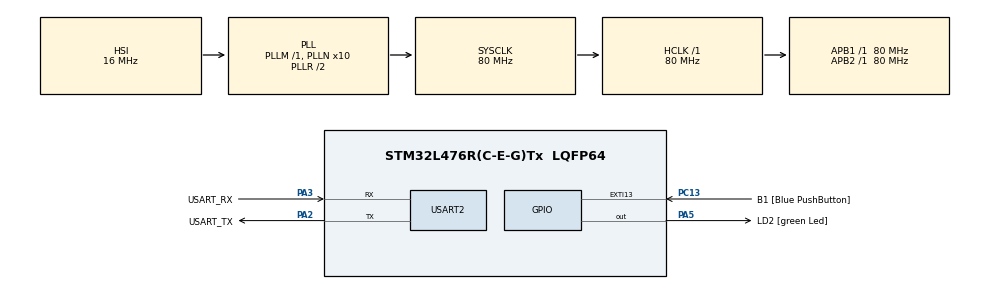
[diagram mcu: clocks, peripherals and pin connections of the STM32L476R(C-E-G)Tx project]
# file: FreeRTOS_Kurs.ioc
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ADC1.Channel-0\#ChannelRegularConversion=ADC_CHANNEL_TEMPSENSOR
ADC1.ContinuousConvMode=DISABLE
ADC1.NbrOfConversionFlag=1
ADC1.OffsetNumber-0\#ChannelRegularConversion=ADC_OFFSET_NONE
ADC1.Rank-0\#ChannelRegularConversion=1
ADC1.SamplingTime-0\#ChannelRegularConversion=ADC_SAMPLETIME_640CYCLES_5
ADC1.master=1
Dma.Request0=USART2_TX
Dma.USART2_TX.0.Direction=DMA_MEMORY_TO_PERIPH
Dma.USART2_TX.0.Instance=DMA1_Channel7
Dma.USART2_TX.0.MemDataAlignment=DMA_MDATAALIGN_BYTE
Dma.USART2_TX.0.MemInc=DMA_MINC_ENABLE
Dma.USART2_TX.0.Mode=DMA_NORMAL
Dma.USART2_TX.0.PeriphDataAlignment=DMA_PDATAALIGN_BYTE
Dma.USART2_TX.0.PeriphInc=DMA_PINC_DISABLE
Dma.USART2_TX.0.Priority=DMA_PRIORITY_LOW
FREERTOS.Tasks01=UartTxTask,24,512,StartUartTxTask,As weak,NULL,Static,UartTxTaskBuffer,UartTxTaskControlBlock;TelemetryTask,40,384,StartTelemetryTask,As external,NULL,Static,TelemetryTaskBuffer,TelemetryTaskControlBlock;ButtonTask,32,256,StartButtonTask,As external,NULL,Static,ButtonTaskBuffer,ButtonTaskControlBlock
FREERTOS.configCHECK_FOR_STACK_OVERFLOW=2
FREERTOS.configGENERATE_RUN_TIME_STATS=1
FREERTOS.configTOTAL_HEAP_SIZE=16384
FREERTOS.configUSE_APPLICATION_TASK_TAG=1
FREERTOS.configUSE_MALLOC_FAILED_HOOK=1
FREERTOS.configUSE_NEWLIB_REENTRANT=1
Mcu.Family=STM32L4
Mcu.Name=STM32L476R(C-E-G)Tx
Mcu.Package=LQFP64
NVIC.DMA1_Channel7_IRQn=true\:6\:0\:true\:false\:true\:true\:false\:true\:true
NVIC.EXTI15_10_IRQn=true\:6\:0\:true\:false\:true\:true\:true\:true\:true
NVIC.PriorityGroup=NVIC_PRIORITYGROUP_4
NVIC.TIM6_DAC_IRQn=true\:15\:0\:false\:false\:true\:false\:false\:true\:true
NVIC.TimeBase=TIM6_DAC_IRQn
NVIC.TimeBaseIP=TIM6
NVIC.USART2_IRQn=true\:6\:0\:true\:false\:true\:true\:true\:true\:true
PA13\ (JTMS-SWDIO).GPIO_Label=TMS
PA13\ (JTMS-SWDIO).Mode=Serial_Wire
PA13\ (JTMS-SWDIO).Signal=SYS_JTMS-SWDIO
PA14\ (JTCK-SWCLK).GPIO_Label=TCK
PA14\ (JTCK-SWCLK).Mode=Serial_Wire
PA14\ (JTCK-SWCLK).Signal=SYS_JTCK-SWCLK
PA2.GPIO_Label=USART_TX
PA2.GPIO_Mode=GPIO_MODE_AF_PP
PA2.GPIO_PuPd=GPIO_NOPULL
PA2.GPIO_Speed=GPIO_SPEED_FREQ_VERY_HIGH
PA2.Mode=Asynchronous
PA2.Signal=USART2_TX
PA3.GPIO_Label=USART_RX
PA3.GPIO_Mode=GPIO_MODE_AF_PP
PA3.GPIO_PuPd=GPIO_NOPULL
PA3.GPIO_Speed=GPIO_SPEED_FREQ_VERY_HIGH
PA3.Mode=Asynchronous
PA3.Signal=USART2_RX
PA5.GPIO_Label=LD2 [green Led]
PA5.GPIO_ModeDefaultOutputPP=GPIO_MODE_OUTPUT_PP
PA5.GPIO_PuPd=GPIO_NOPULL
PA5.GPIO_Speed=GPIO_SPEED_FREQ_LOW
PA5.Signal=GPIO_Output
PB3\ (JTDO-TRACESWO).GPIO_Label=SWO
PB3\ (JTDO-TRACESWO).Signal=SYS_JTDO-SWO
PC13.GPIO_Label=B1 [Blue PushButton]
PC13.GPIO_ModeDefaultEXTI=GPIO_MODE_IT_FALLING
PC13.GPIO_PuPd=GPIO_NOPULL
PC13.Signal=GPXTI13
PC14-OSC32_IN\ (PC14).Mode=LSE-External-Oscillator
PC14-OSC32_IN\ (PC14).Signal=RCC_OSC32_IN
PC15-OSC32_OUT\ (PC15).Mode=LSE-External-Oscillator
PC15-OSC32_OUT\ (PC15).Signal=RCC_OSC32_OUT
PH0-OSC_IN\ (PH0).Signal=RCC_OSC_IN
PH1-OSC_OUT\ (PH1).Signal=RCC_OSC_OUT
ProjectManager.HeapSize=0x200
ProjectManager.StackSize=0x400
ProjectManager.TargetToolchain=STM32CubeIDE
RCC.ADCFreq_Value=64000000
RCC.AHBFreq_Value=80000000
RCC.APB1Freq_Value=80000000
RCC.APB1TimFreq_Value=80000000
RCC.APB2Freq_Value=80000000
RCC.APB2TimFreq_Value=80000000
RCC.CortexFreq_Value=80000000
RCC.HCLKFreq_Value=80000000
RCC.HSE_VALUE=8000000
RCC.HSI_VALUE=16000000
RCC.MSI_VALUE=4000000
RCC.PLLN=10
RCC.PLLSourceVirtual=RCC_PLLSOURCE_HSI
RCC.PREFETCH_ENABLE=1
RCC.SYSCLKFreq_VALUE=80000000
RCC.SYSCLKSource=RCC_SYSCLKSOURCE_PLLCLK
RCC.USBFreq_Value=64000000
RCC.VCOOutputFreq_Value=160000000
TIM2.Prescaler=79
USART2.VirtualMode-Asynchronous=VM_ASYNC
VP_ADC1_TempSens_Input.Mode=IN-TempSens
VP_FREERTOS_VS_CMSIS_V2.Mode=CMSIS_V2
VP_SYS_VS_tim6.Mode=TIM6
VP_TIM2_VS_ClockSourceINT.Mode=Internal
board=NUCLEO-L476RG

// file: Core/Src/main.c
/* USER CODE BEGIN Header */
/**
  ******************************************************************************
  * @file           : main.c
  * @brief          : Main program body
  ******************************************************************************
  * @attention
  *
  * Copyright (c) 2026 STMicroelectronics.
  * All rights reserved.
  *
  * This software is licensed under terms that can be found in the LICENSE file
  * in the root directory of this software component.
  * If no LICENSE file comes with this software, it is provided AS-IS.
  *
  ******************************************************************************
  */
/* USER CODE END Header */
#include "main.h"
#include "cmsis_os.h"

/* USER CODE BEGIN Includes */
#include "app_ts.h"
#include "app_run.h"

/* USER CODE END Includes */

typedef StaticTask_t osStaticThreadDef_t;

ADC_HandleTypeDef hadc1;

TIM_HandleTypeDef htim2;

UART_HandleTypeDef huart2;
DMA_HandleTypeDef hdma_usart2_tx;

/* Definitions for UartTxTask */
osThreadId_t UartTxTaskHandle;
uint32_t UartTxTaskBuffer[ 512 ];
osStaticThreadDef_t UartTxTaskControlBlock;
const osThreadAttr_t UartTxTask_attributes = {
  .name = "UartTxTask",
  .cb_mem = &UartTxTaskControlBlock,
  .cb_size = sizeof(UartTxTaskControlBlock),
  .stack_mem = &UartTxTaskBuffer[0],
  .stack_size = sizeof(UartTxTaskBuffer),
  .priority = (osPriority_t) osPriorityNormal,
};
/* Definitions for TelemetryTask */
osThreadId_t TelemetryTaskHandle;
uint32_t TelemetryTaskBuffer[ 384 ];
osStaticThreadDef_t TelemetryTaskControlBlock;
const osThreadAttr_t TelemetryTask_attributes = {
  .name = "TelemetryTask",
  .cb_mem = &TelemetryTaskControlBlock,
  .cb_size = sizeof(TelemetryTaskControlBlock),
  .stack_mem = &TelemetryTaskBuffer[0],
  .stack_size = sizeof(TelemetryTaskBuffer),
  .priority = (osPriority_t) osPriorityHigh,
};
/* Definitions for ButtonTask */
osThreadId_t ButtonTaskHandle;
uint32_t ButtonTaskBuffer[ 256 ];
osStaticThreadDef_t ButtonTaskControlBlock;
const osThreadAttr_t ButtonTask_attributes = {
  .name = "ButtonTask",
  .cb_mem = &ButtonTaskControlBlock,
  .cb_size = sizeof(ButtonTaskControlBlock),
  .stack_mem = &ButtonTaskBuffer[0],
  .stack_size = sizeof(ButtonTaskBuffer),
  .priority = (osPriority_t) osPriorityAboveNormal,
};

void SystemClock_Config(void);
static void MX_GPIO_Init(void);
static void MX_DMA_Init(void);
static void MX_USART2_UART_Init(void);
static void MX_ADC1_Init(void);
static void MX_TIM2_Init(void);
void StartUartTxTask(void *argument);
extern void StartTelemetryTask(void *argument);
extern void StartButtonTask(void *argument);

int main(void)
{

  /* MCU Configuration--------------------------------------------------------*/

  /* Reset of all peripherals, Initializes the Flash interface and the Systick. */
  HAL_Init();

  /* Configure the system clock */
  SystemClock_Config();

  /* Initialize all configured peripherals */
  MX_GPIO_Init();
  MX_DMA_Init();
  MX_USART2_UART_Init();
  MX_ADC1_Init();
  MX_TIM2_Init();
  /* USER CODE BEGIN 2 */
  /* Zaman damgası sayacı (TIM2, 1 MHz) ve DWT çevrim sayacı: scheduler'dan önce başlar (tasarım §4). */
  if (HAL_TIM_Base_Start(&htim2) != HAL_OK) { Error_Handler(); }
  ts_dwt_init();

  /* USER CODE END 2 */

  /* Init scheduler */
  osKernelInitialize();

  /* USER CODE BEGIN RTOS_QUEUES */
  app_rtos_objects_create();   /* TX kuyruğu: görevler oluşturulmadan ÖNCE (tasarım §5) */
  /* add queues, ... */
  /* USER CODE END RTOS_QUEUES */

  /* Create the thread(s) */
  /* creation of UartTxTask */
  UartTxTaskHandle = osThreadNew(StartUartTxTask, NULL, &UartTxTask_attributes);

  /* creation of TelemetryTask */
  TelemetryTaskHandle = osThreadNew(StartTelemetryTask, NULL, &TelemetryTask_attributes);

  /* creation of ButtonTask */
  ButtonTaskHandle = osThreadNew(StartButtonTask, NULL, &ButtonTask_attributes);

  /* Start scheduler */
  osKernelStart();

  /* We should never get here as control is now taken by the scheduler */

  /* Infinite loop */
  while (1)
  {

  }
}

void SystemClock_Config(void)
{
  RCC_OscInitTypeDef RCC_OscInitStruct = {0};
  RCC_ClkInitTypeDef RCC_ClkInitStruct = {0};

  /** Configure the main internal regulator output voltage
  */
  if (HAL_PWREx_ControlVoltageScaling(PWR_REGULATOR_VOLTAGE_SCALE1) != HAL_OK)
  {
    Error_Handler();
  }

  /** Initializes the RCC Oscillators according to the specified parameters
  * in the RCC_OscInitTypeDef structure.
  */
  RCC_OscInitStruct.OscillatorType = RCC_OSCILLATORTYPE_HSI;
  RCC_OscInitStruct.HSIState = RCC_HSI_ON;
  RCC_OscInitStruct.HSICalibrationValue = RCC_HSICALIBRATION_DEFAULT;
  RCC_OscInitStruct.PLL.PLLState = RCC_PLL_ON;
  RCC_OscInitStruct.PLL.PLLSource = RCC_PLLSOURCE_HSI;
  RCC_OscInitStruct.PLL.PLLM = 1;
  RCC_OscInitStruct.PLL.PLLN = 10;
  RCC_OscInitStruct.PLL.PLLP = RCC_PLLP_DIV7;
  RCC_OscInitStruct.PLL.PLLQ = RCC_PLLQ_DIV2;
  RCC_OscInitStruct.PLL.PLLR = RCC_PLLR_DIV2;
  if (HAL_RCC_OscConfig(&RCC_OscInitStruct) != HAL_OK)
  {
    Error_Handler();
  }

  /** Initializes the CPU, AHB and APB buses clocks
  */
  RCC_ClkInitStruct.ClockType = RCC_CLOCKTYPE_HCLK|RCC_CLOCKTYPE_SYSCLK
                              |RCC_CLOCKTYPE_PCLK1|RCC_CLOCKTYPE_PCLK2;
  RCC_ClkInitStruct.SYSCLKSource = RCC_SYSCLKSOURCE_PLLCLK;
  RCC_ClkInitStruct.AHBCLKDivider = RCC_SYSCLK_DIV1;
  RCC_ClkInitStruct.APB1CLKDivider = RCC_HCLK_DIV1;
  RCC_ClkInitStruct.APB2CLKDivider = RCC_HCLK_DIV1;

  if (HAL_RCC_ClockConfig(&RCC_ClkInitStruct, FLASH_LATENCY_4) != HAL_OK)
  {
    Error_Handler();
  }
}

static void MX_ADC1_Init(void)
{

  ADC_MultiModeTypeDef multimode = {0};
  ADC_ChannelConfTypeDef sConfig = {0};

  /** Common config
  */
  hadc1.Instance = ADC1;
  hadc1.Init.ClockPrescaler = ADC_CLOCK_ASYNC_DIV1;
  hadc1.Init.Resolution = ADC_RESOLUTION_12B;
  hadc1.Init.DataAlign = ADC_DATAALIGN_RIGHT;
  hadc1.Init.ScanConvMode = ADC_SCAN_DISABLE;
  hadc1.Init.EOCSelection = ADC_EOC_SINGLE_CONV;
  hadc1.Init.LowPowerAutoWait = DISABLE;
  hadc1.Init.ContinuousConvMode = DISABLE;
  hadc1.Init.NbrOfConversion = 1;
  hadc1.Init.DiscontinuousConvMode = DISABLE;
  hadc1.Init.ExternalTrigConv = ADC_SOFTWARE_START;
  hadc1.Init.ExternalTrigConvEdge = ADC_EXTERNALTRIGCONVEDGE_NONE;
  hadc1.Init.DMAContinuousRequests = DISABLE;
  hadc1.Init.Overrun = ADC_OVR_DATA_PRESERVED;
  hadc1.Init.OversamplingMode = DISABLE;
  if (HAL_ADC_Init(&hadc1) != HAL_OK)
  {
    Error_Handler();
  }

  /** Configure the ADC multi-mode
  */
  multimode.Mode = ADC_MODE_INDEPENDENT;
  if (HAL_ADCEx_MultiModeConfigChannel(&hadc1, &multimode) != HAL_OK)
  {
    Error_Handler();
  }

  /** Configure Regular Channel
  */
  sConfig.Channel = ADC_CHANNEL_TEMPSENSOR;
  sConfig.Rank = ADC_REGULAR_RANK_1;
  sConfig.SamplingTime = ADC_SAMPLETIME_640CYCLES_5;
  sConfig.SingleDiff = ADC_SINGLE_ENDED;
  sConfig.OffsetNumber = ADC_OFFSET_NONE;
  sConfig.Offset = 0;
  if (HAL_ADC_ConfigChannel(&hadc1, &sConfig) != HAL_OK)
  {
    Error_Handler();
  }

}

static void MX_TIM2_Init(void)
{

  TIM_ClockConfigTypeDef sClockSourceConfig = {0};
  TIM_MasterConfigTypeDef sMasterConfig = {0};

  htim2.Instance = TIM2;
  htim2.Init.Prescaler = 79;
  htim2.Init.CounterMode = TIM_COUNTERMODE_UP;
  htim2.Init.Period = 4294967295;
  htim2.Init.ClockDivision = TIM_CLOCKDIVISION_DIV1;
  htim2.Init.AutoReloadPreload = TIM_AUTORELOAD_PRELOAD_DISABLE;
  if (HAL_TIM_Base_Init(&htim2) != HAL_OK)
  {
    Error_Handler();
  }
  sClockSourceConfig.ClockSource = TIM_CLOCKSOURCE_INTERNAL;
  if (HAL_TIM_ConfigClockSource(&htim2, &sClockSourceConfig) != HAL_OK)
  {
    Error_Handler();
  }
  sMasterConfig.MasterOutputTrigger = TIM_TRGO_RESET;
  sMasterConfig.MasterSlaveMode = TIM_MASTERSLAVEMODE_DISABLE;
  if (HAL_TIMEx_MasterConfigSynchronization(&htim2, &sMasterConfig) != HAL_OK)
  {
    Error_Handler();
  }

}

static void MX_USART2_UART_Init(void)
{

  huart2.Instance = USART2;
  huart2.Init.BaudRate = 115200;
  huart2.Init.WordLength = UART_WORDLENGTH_8B;
  huart2.Init.StopBits = UART_STOPBITS_1;
  huart2.Init.Parity = UART_PARITY_NONE;
  huart2.Init.Mode = UART_MODE_TX_RX;
  huart2.Init.HwFlowCtl = UART_HWCONTROL_NONE;
  huart2.Init.OverSampling = UART_OVERSAMPLING_16;
  huart2.Init.OneBitSampling = UART_ONE_BIT_SAMPLE_DISABLE;
  huart2.AdvancedInit.AdvFeatureInit = UART_ADVFEATURE_NO_INIT;
  if (HAL_UART_Init(&huart2) != HAL_OK)
  {
    Error_Handler();
  }

}

static void MX_DMA_Init(void)
{

  /* DMA controller clock enable */
  __HAL_RCC_DMA1_CLK_ENABLE();

  /* DMA interrupt init */
  /* DMA1_Channel7_IRQn interrupt configuration */
  HAL_NVIC_SetPriority(DMA1_Channel7_IRQn, 6, 0);
  HAL_NVIC_EnableIRQ(DMA1_Channel7_IRQn);

}

static void MX_GPIO_Init(void)
{
  GPIO_InitTypeDef GPIO_InitStruct = {0};

  /* GPIO Ports Clock Enable */
  __HAL_RCC_GPIOC_CLK_ENABLE();
  __HAL_RCC_GPIOH_CLK_ENABLE();
  __HAL_RCC_GPIOA_CLK_ENABLE();
  __HAL_RCC_GPIOB_CLK_ENABLE();

  /*Configure GPIO pin Output Level */
  HAL_GPIO_WritePin(LD2_GPIO_Port, LD2_Pin, GPIO_PIN_RESET);

  /*Configure GPIO pin : B1_Pin */
  GPIO_InitStruct.Pin = B1_Pin;
  GPIO_InitStruct.Mode = GPIO_MODE_IT_FALLING;
  GPIO_InitStruct.Pull = GPIO_NOPULL;
  HAL_GPIO_Init(B1_GPIO_Port, &GPIO_InitStruct);

  /*Configure GPIO pin : LD2_Pin */
  GPIO_InitStruct.Pin = LD2_Pin;
  GPIO_InitStruct.Mode = GPIO_MODE_OUTPUT_PP;
  GPIO_InitStruct.Pull = GPIO_NOPULL;
  GPIO_InitStruct.Speed = GPIO_SPEED_FREQ_LOW;
  HAL_GPIO_Init(LD2_GPIO_Port, &GPIO_InitStruct);

  /* EXTI interrupt init*/
  HAL_NVIC_SetPriority(EXTI15_10_IRQn, 6, 0);
  HAL_NVIC_EnableIRQ(EXTI15_10_IRQn);

}

__weak void StartUartTxTask(void *argument)
{
  for(;;)
  {
    osDelay(1);
  }
}

void HAL_TIM_PeriodElapsedCallback(TIM_HandleTypeDef *htim)
{
  if (htim->Instance == TIM6)
  {
    HAL_IncTick();
  }
}

void Error_Handler(void)
{
  __disable_irq();
  while (1)
  {
  }
}

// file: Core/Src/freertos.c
/* USER CODE BEGIN Header */
/**
  ******************************************************************************
  * File Name          : freertos.c
  * Description        : Code for freertos applications
  ******************************************************************************
  * @attention
  *
  * Copyright (c) 2026 STMicroelectronics.
  * All rights reserved.
  *
  * This software is licensed under terms that can be found in the LICENSE file
  * in the root directory of this software component.
  * If no LICENSE file comes with this software, it is provided AS-IS.
  *
  ******************************************************************************
  */
/* USER CODE END Header */

#include "FreeRTOS.h"
#include "task.h"
#include "main.h"

/* USER CODE BEGIN Includes */
#include "app_fault.h"

/* USER CODE END Includes */

/* Hook prototypes */
void configureTimerForRunTimeStats(void);
unsigned long getRunTimeCounterValue(void);
void vApplicationStackOverflowHook(xTaskHandle xTask, signed char *pcTaskName);
void vApplicationMallocFailedHook(void);

/* USER CODE BEGIN 1 */
/* Functions needed when configGENERATE_RUN_TIME_STATS is on */
__weak void configureTimerForRunTimeStats(void)
{

}

__weak unsigned long getRunTimeCounterValue(void)
{
return 0;
}
/* USER CODE END 1 */

/* USER CODE BEGIN 4 */
void vApplicationStackOverflowHook(xTaskHandle xTask, signed char *pcTaskName)
{
   /* Run time stack overflow checking is performed if
   configCHECK_FOR_STACK_OVERFLOW is defined to 1 or 2. This hook function is
   called if a stack overflow is detected. */
   app_fault_blink(10);   /* SYS-05: LD2 10 Hz (tasarım §10) */
}
/* USER CODE END 4 */

/* USER CODE BEGIN 5 */
void vApplicationMallocFailedHook(void)
{
   /* vApplicationMallocFailedHook() will only be called if
   configUSE_MALLOC_FAILED_HOOK is set to 1 in FreeRTOSConfig.h. It is a hook
   function that will get called if a call to pvPortMalloc() fails.
   pvPortMalloc() is called internally by the kernel whenever a task, queue,
   timer or semaphore is created. It is also called by various parts of the
   demo application. If heap_1.c or heap_2.c are used, then the size of the
   heap available to pvPortMalloc() is defined by configTOTAL_HEAP_SIZE in
   FreeRTOSConfig.h, and the xPortGetFreeHeapSize() API function can be used
   to query the size of free heap space that remains (although it does not
   provide information on how the remaining heap might be fragmented). */
   app_fault_blink(2);    /* LD2 2 Hz (tasarım §10) */
}
/* USER CODE END 5 */
